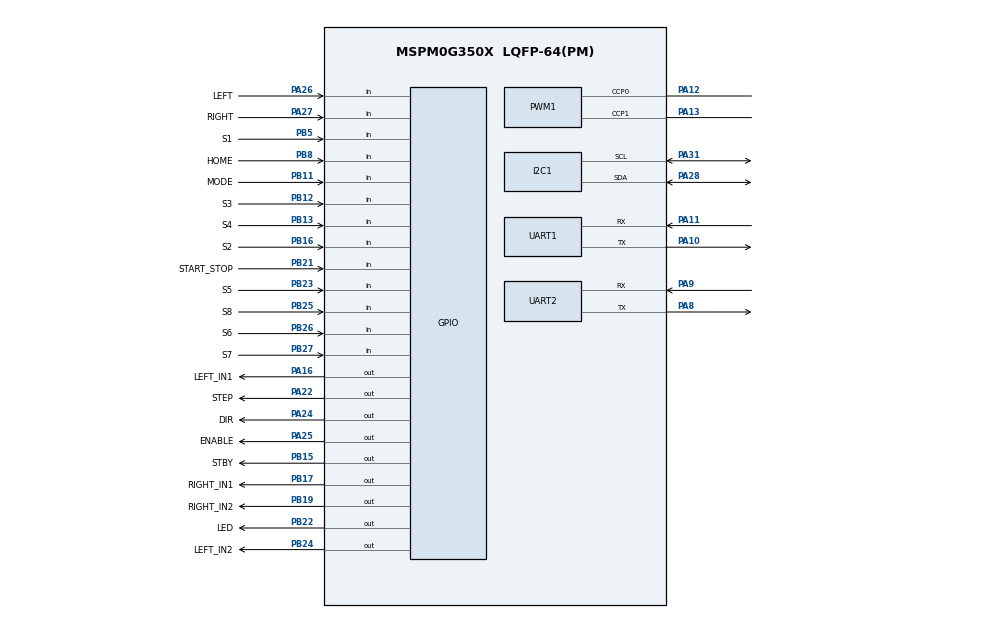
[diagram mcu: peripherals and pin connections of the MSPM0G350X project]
/**
 * H1_H5_TIANMENG: Q1-Q5 integration with SSD1306 and A4988.
 *
 * @cliArgs --device "MSPM0G350X" --part "Default" --package "LQFP-64(PM)" --product "mspm0_sdk@2.11.00.07"
 * @versions {"tool":"1.26.2+4477"}
 */

const GPIO   = scripting.addModule("/ti/driverlib/GPIO", {}, false);
const GPIO1  = GPIO.addInstance();
const GPIO2  = GPIO.addInstance();
const GPIO3  = GPIO.addInstance();
const GPIO4  = GPIO.addInstance();
const GPIO5  = GPIO.addInstance();
const GPIO6  = GPIO.addInstance();
const GPIO7  = GPIO.addInstance();
const I2C    = scripting.addModule("/ti/driverlib/I2C", {}, false);
const I2C1   = I2C.addInstance();
const PWM    = scripting.addModule("/ti/driverlib/PWM", {}, false);
const PWM1   = PWM.addInstance();
const SYSCTL = scripting.addModule("/ti/driverlib/SYSCTL");
const TIMER  = scripting.addModule("/ti/driverlib/TIMER", {}, false);
const TIMER1 = TIMER.addInstance();
const TIMER2 = TIMER.addInstance();
const UART   = scripting.addModule("/ti/driverlib/UART", {}, false);
const UART1  = UART.addInstance();
const UART2  = UART.addInstance();

/* Tianmengxing on-board user LED, active high. */
GPIO1.$name                          = "STATUS_LED";
GPIO1.associatedPins.create(1);
GPIO1.associatedPins[0].$name        = "LED";
GPIO1.associatedPins[0].initialValue = "CLEARED";
GPIO1.associatedPins[0].pin.$assign  = "PB22";

/* External D24A standby. Keep low throughout reset and initialization. */
GPIO2.$name                          = "DRV_SAFE";
GPIO2.associatedPins.create(1);
GPIO2.associatedPins[0].$name        = "STBY";
GPIO2.associatedPins[0].initialValue = "CLEARED";
GPIO2.associatedPins[0].pin.$assign  = "PB15";

/* D24A groups: A+B are right, C+D are left. */
GPIO3.$name = "MOTOR_DIR";
GPIO3.associatedPins.create(4);
GPIO3.associatedPins[0].$name = "RIGHT_IN1";
GPIO3.associatedPins[0].initialValue = "CLEARED";
GPIO3.associatedPins[0].pin.$assign = "PB17";
GPIO3.associatedPins[1].$name = "RIGHT_IN2";
GPIO3.associatedPins[1].initialValue = "CLEARED";
GPIO3.associatedPins[1].pin.$assign = "PB19";
GPIO3.associatedPins[2].$name = "LEFT_IN1";
GPIO3.associatedPins[2].initialValue = "CLEARED";
GPIO3.associatedPins[2].pin.$assign = "PA16";
GPIO3.associatedPins[3].$name = "LEFT_IN2";
GPIO3.associatedPins[3].initialValue = "CLEARED";
GPIO3.associatedPins[3].pin.$assign = "PB24";

/* S1 is left-most when looking in the car's forward direction. */
GPIO4.$name = "LINE_SENSOR";
GPIO4.associatedPins.create(8);
GPIO4.associatedPins[0].$name = "S1";
GPIO4.associatedPins[0].direction = "INPUT";
GPIO4.associatedPins[0].pin.$assign = "PB5";
GPIO4.associatedPins[1].$name = "S2";
GPIO4.associatedPins[1].direction = "INPUT";
GPIO4.associatedPins[1].pin.$assign = "PB16";
GPIO4.associatedPins[2].$name = "S3";
GPIO4.associatedPins[2].direction = "INPUT";
GPIO4.associatedPins[2].pin.$assign = "PB12";
GPIO4.associatedPins[3].$name = "S4";
GPIO4.associatedPins[3].direction = "INPUT";
GPIO4.associatedPins[3].pin.$assign = "PB13";
GPIO4.associatedPins[4].$name = "S5";
GPIO4.associatedPins[4].direction = "INPUT";
GPIO4.associatedPins[4].pin.$assign = "PB23";
GPIO4.associatedPins[5].$name = "S6";
GPIO4.associatedPins[5].direction = "INPUT";
GPIO4.associatedPins[5].pin.$assign = "PB26";
GPIO4.associatedPins[6].$name = "S7";
GPIO4.associatedPins[6].direction = "INPUT";
GPIO4.associatedPins[6].pin.$assign = "PB27";
GPIO4.associatedPins[7].$name = "S8";
GPIO4.associatedPins[7].direction = "INPUT";
GPIO4.associatedPins[7].pin.$assign = "PB25";

/* Tianmengxing on-board key, active low. */
GPIO5.$name = "USER_INPUT";
GPIO5.associatedPins.create(1);
GPIO5.associatedPins[0].$name = "START_STOP";
GPIO5.associatedPins[0].direction = "INPUT";
GPIO5.associatedPins[0].internalResistor = "PULL_UP";
GPIO5.associatedPins[0].pin.$assign = "PB21";

/* A4988 on external headers; ENABLE is active low and defaults disabled. */
GPIO6.$name = "A4988_IO";
GPIO6.associatedPins.create(4);
GPIO6.associatedPins[0].$name = "STEP";
GPIO6.associatedPins[0].initialValue = "CLEARED";
GPIO6.associatedPins[0].pin.$assign = "PA22";
GPIO6.associatedPins[1].$name = "DIR";
GPIO6.associatedPins[1].initialValue = "CLEARED";
GPIO6.associatedPins[1].pin.$assign = "PA24";
GPIO6.associatedPins[2].$name = "ENABLE";
GPIO6.associatedPins[2].initialValue = "SET";
GPIO6.associatedPins[2].pin.$assign = "PA25";
GPIO6.associatedPins[3].$name = "HOME";
GPIO6.associatedPins[3].direction = "INPUT";
GPIO6.associatedPins[3].internalResistor = "PULL_UP";
GPIO6.associatedPins[3].pin.$assign = "PB8";

/*
 * K2/K3 remain external service keys. MODE uses the expansion-board
 * KEY2 switch, which the trusted schematic connects from PB11 to GND.
 */
GPIO7.$name = "TEACH_KEYS";
GPIO7.associatedPins.create(3);
GPIO7.associatedPins[0].$name = "LEFT";
GPIO7.associatedPins[0].direction = "INPUT";
GPIO7.associatedPins[0].internalResistor = "PULL_UP";
GPIO7.associatedPins[0].pin.$assign = "PA26";
GPIO7.associatedPins[1].$name = "RIGHT";
GPIO7.associatedPins[1].direction = "INPUT";
GPIO7.associatedPins[1].internalResistor = "PULL_UP";
GPIO7.associatedPins[1].pin.$assign = "PA27";
GPIO7.associatedPins[2].$name = "MODE";
GPIO7.associatedPins[2].direction = "INPUT";
GPIO7.associatedPins[2].internalResistor = "PULL_UP";
GPIO7.associatedPins[2].pin.$assign = "PB11";

/* 32 MHz / 1600 = 20 kHz. */
PWM1.$name = "MOTOR_PWM";
PWM1.timerCount = 1600;
PWM1.ccIndex = [0, 1];
PWM1.timerStartTimer = false;
PWM1.peripheral.$assign = "TIMG0";
PWM1.peripheral.ccp0Pin.$assign = "PA12";
PWM1.peripheral.ccp1Pin.$assign = "PA13";
PWM1.PWM_CHANNEL_0.$name = "RIGHT_PWM";
PWM1.PWM_CHANNEL_0.dutyCycle = 0;
PWM1.PWM_CHANNEL_1.$name = "LEFT_PWM";
PWM1.PWM_CHANNEL_1.dutyCycle = 0;

/* Expansion-board OLED header: PA28 SDA, PA31 SCL (SSD1306 I2C). */
I2C1.$name = "OLED_I2C";
I2C1.basicEnableController = true;
I2C1.basicControllerStandardBusSpeed = "Fast";
I2C1.advAnalogGlitchFilter = "DISABLED";
I2C1.advControllerTXFIFOTRIG = "BYTES_1";
I2C1.peripheral.$assign = "I2C0";
I2C1.peripheral.sdaPin.$assign = "PA28";
I2C1.peripheral.sclPin.$assign = "PA31";
I2C1.sdaPinConfig.enableConfig = true;
I2C1.sclPinConfig.enableConfig = true;

TIMER1.$name = "CONTROL_TICK";
TIMER1.timerMode = "PERIODIC";
TIMER1.timerPeriod = "5 ms";
TIMER1.timerClkPrescale = 8;
TIMER1.interrupts = ["ZERO"];

TIMER2.$name = "STEPPER_TICK";
TIMER2.timerMode = "PERIODIC";
TIMER2.timerPeriod = "100 us";
TIMER2.timerClkPrescale = 1;
TIMER2.interrupts = ["ZERO"];
TIMER2.peripheral.$assign = "TIMG8";

SYSCTL.forceDefaultClkConfig = true;
SYSCTL.clockTreeEn = true;

/* Tianmengxing on-board CH340. */
UART1.$name = "DEBUG_UART";
UART1.enableFIFO = true;
UART1.enableDMARX = false;
UART1.enableDMATX = false;
UART1.targetBaudRate = 115200;
UART1.enableInternalLoopback = false;
UART1.rxFifoThreshold = "DL_UART_RX_FIFO_LEVEL_1_2_FULL";
UART1.peripheral.$assign = "UART0";
UART1.peripheral.rxPin.$assign = "PA11";
UART1.peripheral.txPin.$assign = "PA10";

/*
 * K230 UART1_TX is received on the expansion-board H2 connector PA9.
 * PA8 is reserved as the matching UART1 TX pin but is not wired initially.
 */
UART2.$name = "BALL_UART";
UART2.enableFIFO = false;
UART2.targetBaudRate = 115200;
UART2.enableInternalLoopback = false;
UART2.enabledInterrupts = ["RX"];
UART2.peripheral.$assign = "UART1";
UART2.peripheral.rxPin.$assign = "PA9";
UART2.peripheral.txPin.$assign = "PA8";

const Board = scripting.addModule("/ti/driverlib/Board", {}, false);
